# STM32MP25_CM33 register map
File version: 1.3
CPU: CM33 r0p1, little endian, MPU, FPU, vendor SysTick, 8 interrupt priority bits
Registers are 32-bit, read-write, reset 0x0 unless marked. A register's access mark holds for its fields unless they carry their own. Offsets are from the block's base; [hi:lo] are bit positions; {n}, {i} and the like mark numbered series; 'fields as' and 'values as' point back to an identical list.

## LVDS — LVDS address block description
Base 0x48060000
Same registers: LVDS_S 0x58060000
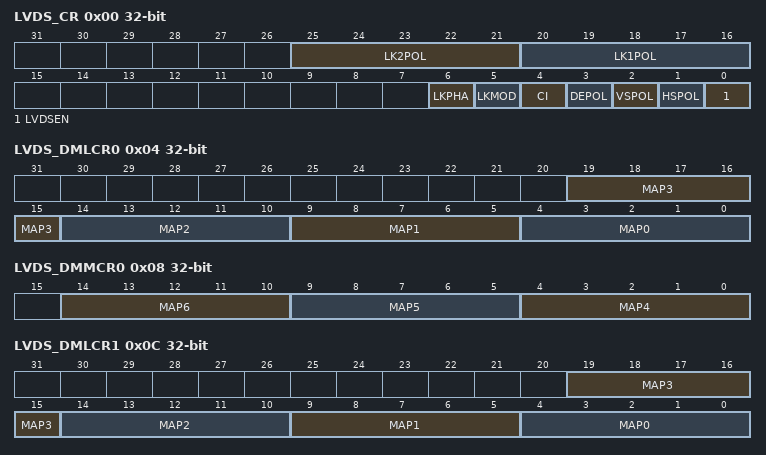
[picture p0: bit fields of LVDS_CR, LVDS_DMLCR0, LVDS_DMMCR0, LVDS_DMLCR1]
0x00 LVDS_CR — LVDS configuration register
  [25:21] LK2POL — Link-2 output polarity, defined per output data/clock lane, from Lane-[4:0]
    0=unchanged polarity; 1=inverted polarity
  [20:16] LK1POL — Link-1 output polarity, defined per output data/clock lane, from Lane-[4:0]
    0=unchanged polarity; 1=inverted polarity
  [6] LKPHA — Link phase, for both links
    0=Even pixel after odd pixel; 1=Even pixel before odd pixel
  [5] LKMOD — Link mode, for both links, which impacts the clock used The LVDS PHY generates a clock at double the pixel rate: in Single-link mode, the pixel generation is set at half the double-pixel-rate clock, while in Dual-link mode, the pixel generation is done at the double-pixel-rate, as each PHY receives half the pixel rate (seeFigure466: Display subsystem clock diagram).
    0=Single-link mode (all pixels sent to both links); 1=Dual-link mode (pixels shared between two links: even pixels to one link, odd to theother)
  [4] CI — Control internal (software controlled bit, that can be inserted among output data)
    0=a 1 and apos;b0 is inserted; 1=a 1 and apos;b1 is inserted
  [3] DEPOL — Data enable polarity
    0=unchanged polarity; 1=inverted polarity
  [2] VSPOL — Vertical synchronization polarity
    0=unchanged polarity; 1=inverted polarity
  [1] HSPOL — Horizontal synchronization polarity
    0=unchanged polarity; 1=inverted polarity
  [0] LVDSEN — LVDS PHY enable
    0=display inactive (no active pixel among the synchronization); 1=display active (active pixels among synchronization)
0x04 LVDS_DMLCR0 — LVDS data mapping LSB configuration register 0
  [19:15] MAP3 — Mapping for bit 3 of that data lane (same content definition as LVDS_DMLCR0.MAP0)
  [14:10] MAP2 — Mapping for bit 2 of that data lane (same content definition as LVDS_DMLCR0.MAP0)
  [9:5] MAP1 — Mapping for bit 1 of that data lane (same content definition as LVDS_DMLCR0.MAP0)
  [4:0] MAP0 — Mapping for bit 0 of that data lane
    0=R0; 7=R7; 8=G0; 15=G7; 16=B0; 23=B7; 24=HS (horizontal synchronization); 25=VS (vertical synchronization); 26=DE (data enable); 27=CE (constant hardware input); 28=CI (constant software input, defined in LVDS_CR.CI); 29=TOGGLE; 30=1 (constant 1&b1); 31=0 (constant 1&b0)
0x08 LVDS_DMMCR0 — LVDS data mapping MSB configuration register 0
  [14:10] MAP6 — Mapping for bit 6 of that data lane (same content definition as LVDS_DMLCR0.MAP0)
  [9:5] MAP5 — Mapping for bit 5 of that data lane (same content definition as LVDS_DMLCR0.MAP0)
  [4:0] MAP4 — Mapping for bit 4 of that data lane (same content definition as LVDS_DMLCR0.MAP0)
0x0C LVDS_DMLCR1 — LVDS data mapping LSB configuration register 1
  fields as LVDS_DMLCR0
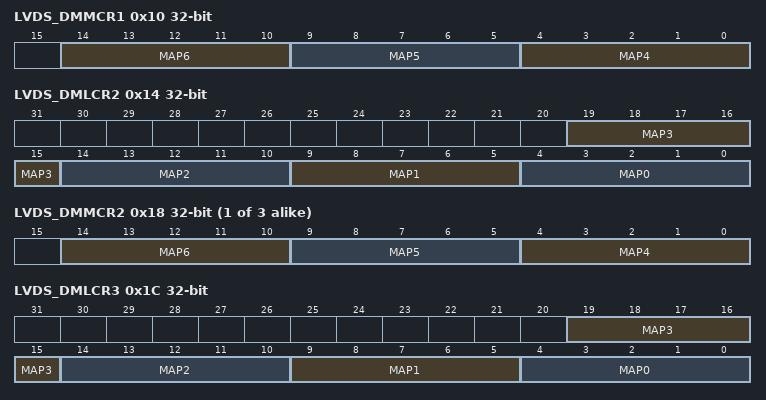
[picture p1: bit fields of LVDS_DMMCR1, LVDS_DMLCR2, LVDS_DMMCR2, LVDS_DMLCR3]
0x10 LVDS_DMMCR1 — LVDS data mapping MSB configuration register 1
  fields as LVDS_DMMCR0
0x14 LVDS_DMLCR2 — LVDS data mapping LSB configuration register 2
  [19:15] MAP3 — Mapping for bit 3 of that DataLane. (same content definition as LVDS_DMLCR0.MAP0)
  [14:10] MAP2 — Mapping for bit 2 of that DataLane. (same content definition as LVDS_DMLCR0.MAP0)
  [9:5] MAP1 — Mapping for bit 1 of that DataLane. (same content definition as LVDS_DMLCR0.MAP0)
  [4:0] MAP0 — Mapping for bit 0 of that DataLane.
    values as LVDS_DMLCR0.MAP0
{0x8+8i} LVDS_DMMCR{i} (i=2..4) — LVDS data mapping MSB configuration register {i}
  [14:10] MAP6 — Mapping for bit 6 of that DataLane. (same content definition as LVDS_DMLCR0.MAP0)
  [9:5] MAP5 — Mapping for bit 5 of that DataLane. (same content definition as LVDS_DMLCR0.MAP0)
  [4:0] MAP4 — Mapping for bit 4 of that DataLane. (same content definition as LVDS_DMLCR0.MAP0)
0x1C LVDS_DMLCR3 — LVDS data mapping LSB configuration register 3
  [19:15] MAP3 — Mapping for bit 3 of that DataLane. (same content definition as LVDS_DMLCR0.MAP0)
  [14:10] MAP2 — Mapping for bit 2 of that DataLane. (same content definition as LVDS_DMLCR0.MAP0)
  [9:5] MAP1 — Mapping for bit 1 of that DataLane. (same content definition as LVDS_DMLCR0.MAP0)
  [4:0] MAP0 — Mapping for bit 0 of that DataLane.
    0=R0; 7=R7; 8=G0; 15=G7; 16=B0; 23=B7; 24=HS (horizontal synchronization); 25=VS (vertical synchronization); 26=DE (data enable); 27=CE (constant hardware input); 28=CI (constant software input, defined in LVDS_CR.CI); 29=TOGGLE; 30=1 (constant 1and apos; b1); 31=0 (constant 1and apos; b0)
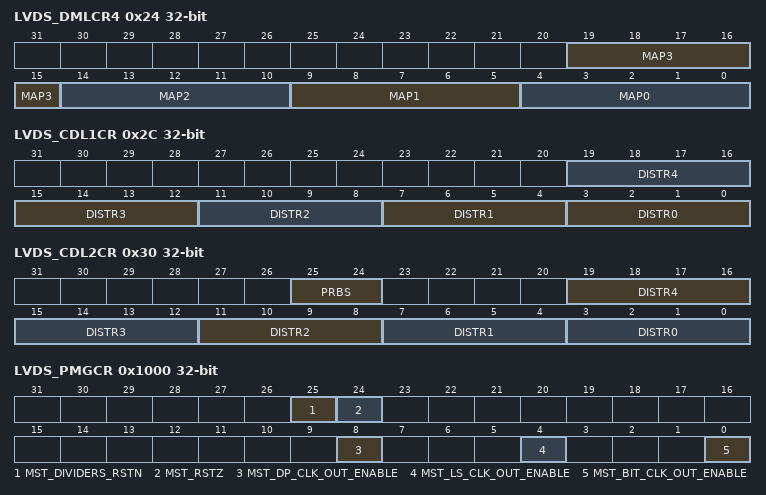
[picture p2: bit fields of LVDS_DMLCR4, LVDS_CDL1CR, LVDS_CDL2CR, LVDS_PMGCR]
0x24 LVDS_DMLCR4 — LVDS data mapping LSB configuration register 4
  fields as LVDS_DMLCR2
0x2C LVDS_CDL1CR — LVDS channel distribution link 1configuration register
  [4n+3:4n] DISTR{n} (n=1..4) — channel distribution for Lane {n} (same content definition as LVDS_CDL1CR.DISTR0)
  [3:0] DISTR0 — channel distribution for Lane 0 Other: Reserved
    {v}=Channel {v} odd (v=0..4); {v}=Channel {v-5} even (v=5..9); 10=PRBS
0x30 LVDS_CDL2CR — LVDS channel distribution link 2 configuration register
  [25:24] PRBS — PRBS polynomial type
    0=PRBS7, with: x7 + x6 + 1; 1=PRBS15, with: x15 + x14 + 1; 2=PRBS23, with: x23 + x18 + 1; 3=PRBS31, with: x31 + x28 + 1
  [4n+3:4n] DISTR{n} (n=1..4) — channel distribution for Lane {n} (same content definition as LVDS_CDL1CR.DISTR0)
  [3:0] DISTR0 — channel distribution for Lane 0 Other: Reserved
    0=Channel 0 odd; 1=Channel 1 even; 2=Channel 2 odd; 3=Channel 3 even; 4=Channel 4 odd; 5=Channel 0 even; 6=Channel 6 odd; 7=Channel 7 even; 8=Channel 8 odd; 9=Channel 4 even; 10=PRBS
0x1000 LVDS_PMGCR — LVDS PHY-Master global control register
  [25] MST_DIVIDERS_RSTN — Output divider reset
    0=output divider is reset; 1=output divider is working
  [24] MST_RSTZ — When set to 0, this bit places the LVDS-PHY digital section in reset state.
  [8] MST_DP_CLK_OUT_ENABLE — Enable LVDS-PHY dp_clk clock
    0=disable; 1=enable
  [4] MST_LS_CLK_OUT_ENABLE — Enable LVDS-PHY ls_clk clock
    0=disable; 1=enable
  [0] MST_BIT_CLK_OUT_ENABLE — Enable LVDS-PHY bit_clk clock
    0=disable; 1=enable
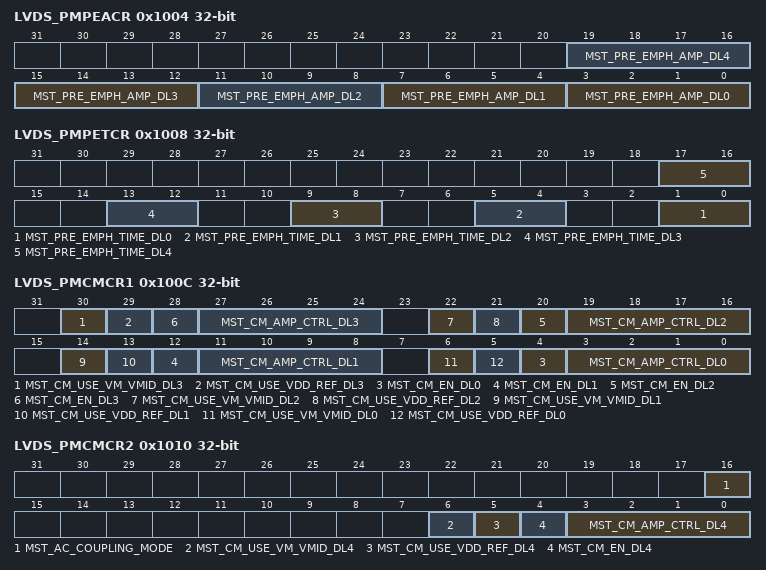
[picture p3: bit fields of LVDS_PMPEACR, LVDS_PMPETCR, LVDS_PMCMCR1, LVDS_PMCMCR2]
0x1004 LVDS_PMPEACR — LVDS PHY-Master pre-emphasis amplitude control register
  [4n+3:4n] MST_PRE_EMPH_AMP_DL{n} (n=1..4) — Amplitude control for pre-emphasis for lane{n}
  [3:0] MST_PRE_EMPH_AMP_DL0 — Amplitude control for pre-mphasis for lane0
0x1008 LVDS_PMPETCR — LVDS PHY-Master pre-emphasis time control register
  [all] fields
    0=no pre-emphasis; 1=1-bit pre-emphasis; 2=1/2 bit pre-emphasis
  [4n+1:4n] MST_PRE_EMPH_TIME_DL{n} (n=0..4) — Time duration control for pre-emphasis for lane{n}
0x100C LVDS_PMCMCR1 — LVDS PHY-Master current mode control register 1
  [30] MST_CM_USE_VM_VMID_DL3 — common mode of datalane3 When high, reference is mid voltage of the driver levels.
  [29] MST_CM_USE_VDD_REF_DL3 — common mode of data lane3 When high, reference is derived from AVDD_IO voltage.
  [8n+4] MST_CM_EN_DL{n} (n=0..3) — Enable for current mode driver, data lane{n}
  [8n+3:8n] MST_CM_AMP_CTRL_DL{n} (n=0..3) — Amplitude control for current mode driver, data lane{n}
  [22] MST_CM_USE_VM_VMID_DL2 — common mode of data lane2 When high, reference is mid voltage of the driver levels.
  [21] MST_CM_USE_VDD_REF_DL2 — common mode of data lane2 When high, reference is derived from AVDD_IO voltage.
  [14] MST_CM_USE_VM_VMID_DL1 — common mode of data lane1 When high, reference is mid voltage of the driver levels.
  [13] MST_CM_USE_VDD_REF_DL1 — common mode of data lane1 When high, reference is derived from AVDD_IO voltage.
  [6] MST_CM_USE_VM_VMID_DL0 — common mode of data lane0 When high, reference is mid voltage of the driver levels.
  [5] MST_CM_USE_VDD_REF_DL0 — common mode of datalane0 When high, reference is derived from AVDD_IO voltage.
0x1010 LVDS_PMCMCR2 — LVDS PHY-Master current mode control register 2
  [16] MST_AC_COUPLING_MODE — AC Coupling Mode.
  [6] MST_CM_USE_VM_VMID_DL4 — common mode of data lane4 When high, reference is mid voltage of the driver level.
  [5] MST_CM_USE_VDD_REF_DL4 — common mode of data lane4 When high, reference is derived from AVDD_IO voltage.
  [4] MST_CM_EN_DL4 — Enable for current mode driver, data lane4
  [3:0] MST_CM_AMP_CTRL_DL4 — Amplitude control for current mode driver, data lane4
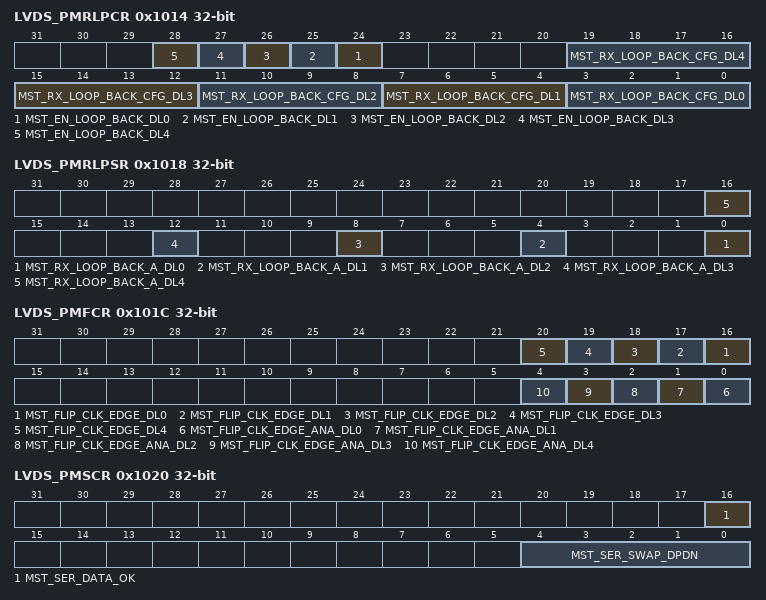
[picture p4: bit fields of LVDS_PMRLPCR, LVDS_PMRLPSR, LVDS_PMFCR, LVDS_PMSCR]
0x1014 LVDS_PMRLPCR — LVDS PHY-Master Rx loopback control register
  [n+24] MST_EN_LOOP_BACK_DL{n} (n=0..4) — Enable the loop back RX used for continuous monitoring, datalane{n}
  [4n+3:4n] MST_RX_LOOP_BACK_CFG_DL{n} (n=0..4) — Rx loop back configuration for data lane{n}
    0=RX input connected to output pads (clk comp: enabled, comp: disabled); 1=RX input connected before termination (clk comp: enabled, comp: disabled); 2=RX input connected to output pads (clk comp: disabled, comp: enabled); 3=RX input connected before termination (clk comp: disabled, comp: enabled)
0x1018 LVDS_PMRLPSR ro — LVDS PHY-master Rx loopback status register
  [4n] MST_RX_LOOP_BACK_A_DL{n} (n=0..4) — Rx loop back output for lane{n}
0x101C LVDS_PMFCR — LVDS PHY-Master flipedge control register
  [n+16] MST_FLIP_CLK_EDGE_DL{n} (n=0..4) — Flips the clock edge used by the first analog stage to resample the incoming data stream, data lane{n}
  [n] MST_FLIP_CLK_EDGE_ANA_DL{n} (n=0..4) — Flips the clock edge used by the pre-driver, data lane{n}
0x1020 LVDS_PMSCR — LVDS PHY-Master serial control register
  [16] MST_SER_DATA_OK — Indicates transmission of data
    0=No transmission; 1=Transmission
  [4:0] MST_SER_SWAP_DPDN — Inverts output data (1 bit per lane
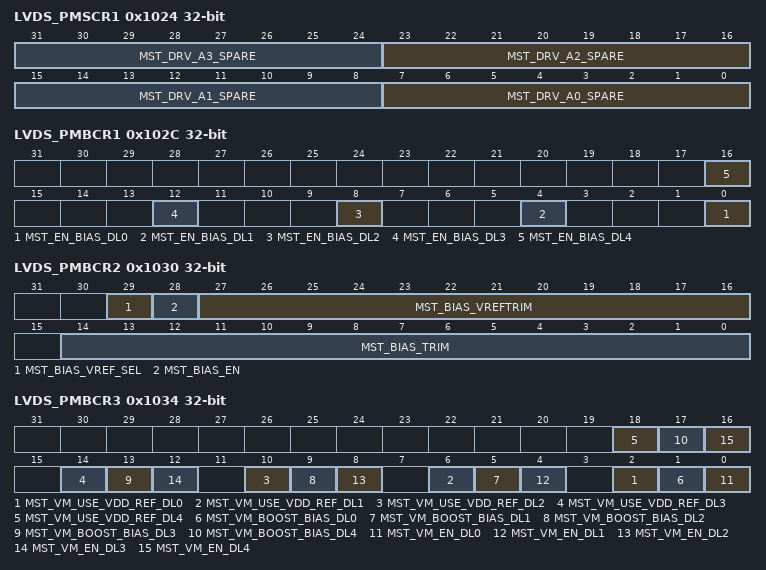
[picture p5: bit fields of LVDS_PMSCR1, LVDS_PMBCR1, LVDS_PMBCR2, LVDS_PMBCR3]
0x1024 LVDS_PMSCR1 — LVDS PHY-Master spare control register 1
  [8n+7:8n] MST_DRV_A{n}_SPARE (n=0..3) — Spare inputs for data lane{n}
0x1028 LVDS_PMSCR2 — LVDS PHY-Master spare control register 2
  [7:0] MST_DRV_A4_SPARE — Spare inputs for data lane4
0x102C LVDS_PMBCR1 — LVDS PHY-Master bias control register 1
  [all] fields
    0=disable; 1=enable
  [4n] MST_EN_BIAS_DL{n} (n=0..4) — Enable the local bias at data lane{n}
0x1030 LVDS_PMBCR2 — LVDS PHY-Master bias control register 2
  [29] MST_BIAS_VREF_SEL — Selection for current generation internal reference
    0=from the bandgap; 1=from an internal resistive divider
  [28] MST_BIAS_EN — LVDS macro global bias enable
    0=disabled; 1=enabled
  [27:16] MST_BIAS_VREFTRIM
    1=0.3961V, 27.01 uA; 2=0.4252 V, 23.36 uA; 4=0.4542 V, 24.96 uA; 8=0.4831 V, 26.57 uA; 16=0.5120 V, 28.21 uA; 32=0.5410 V, 29.90 uA; 64=0.5698 V, 31.66 uA; 128=0.5985 V, 33.54 uA; 0x100=0.6272 V, 35.70 uA; 0x201=0.6557 V, 38.63 uA; 0x400=0.6838 V, 43.98 uA; 0x800=0.7107 V, 56.97 uA
  [14:0] MST_BIAS_TRIM — 0x0: 27.71 uA
    1=27.01 uA; 3=26.32 uA; 7=25.63 uA; 15=24.94 uA; 31=24.24 uA; 63=23.55 uA; 127=22.86 uA; 255=23.55 uA; 0x1FF=24.24 uA; 0x3FF=24.94 uA; 0x7FF=25.63 uA; 0xFFF=26.32 uA; 0x1FFF=27.01 uA; 0x3FFF=27.71 uA; 0x7FFF=28.40 uA
0x1034 LVDS_PMBCR3 — LVDS PHY-Master bias control register 3
  [4n+2] MST_VM_USE_VDD_REF_DL{n} (n=0..4) — Sets the voltage mode driver to use a reference derived from the power supply, data lane{n}
  [4n+1] MST_VM_BOOST_BIAS_DL{n} (n=0..4) — Bias booster for the voltage mode driver LDOS, data lane{n}
    0=bandgap selected; 1=internal resistive divider
  [4n] MST_VM_EN_DL{n} (n=0..4) — Enable the voltage mode driver for data lane{n}
    0=disable; 1=enable
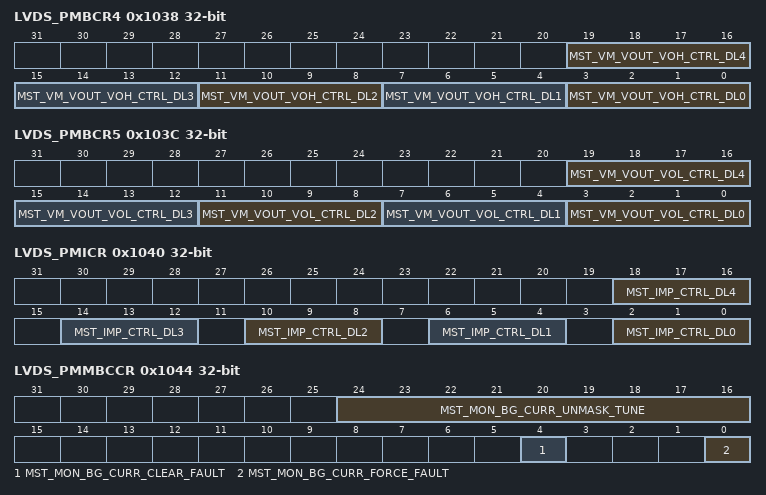
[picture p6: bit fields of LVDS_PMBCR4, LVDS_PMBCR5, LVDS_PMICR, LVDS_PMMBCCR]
0x1038 LVDS_PMBCR4 — LVDS PHY-Master bias control register 4
  [4n+3:4n] MST_VM_VOUT_VOH_CTRL_DL{n} (n=0..4) — Fine tuning for the voltage mode driver VOH, datalane{n}
0x103C LVDS_PMBCR5 — LVDS PHY-Master bias control register 5
  [4n+3:4n] MST_VM_VOUT_VOL_CTRL_DL{n} (n=0..4) — Fine tuning for the voltage mode driver VOL, datalane{n}
0x1040 LVDS_PMICR — LVDS PHY-Master impedance control register
  [18:16] MST_IMP_CTRL_DL4 — Impedance control for data lane4
  [14:12] MST_IMP_CTRL_DL3 — Impedance control for data lane3
  [10:8] MST_IMP_CTRL_DL2 — Impedance control for data lane0
  [6:4] MST_IMP_CTRL_DL1 — Impedance control for data lane1
  [2:0] MST_IMP_CTRL_DL0 — Impedance control for data lane0
0x1044 LVDS_PMMBCCR — LVDS PHY-Master monitor bandgap current control register
  [24:16] MST_MON_BG_CURR_UNMASK_TUNE — Bandgap current timing control for the monitor unmask after startup
  [4] MST_MON_BG_CURR_CLEAR_FAULT — Bandgap current monitor clear fault If set high, lvds_monitor_bg_curr_fault_mst is cleared. It has to be set low again in order to continue monitoring the bandgap current.
  [0] MST_MON_BG_CURR_FORCE_FAULT — Bandgap current monitor force fault If set high, force the lvds_monitor_bg_curr_fault_mst and lvds_monitor_bg_curr_permanent_fault_mst to indicate a fault. This force is only removed once it goes low again
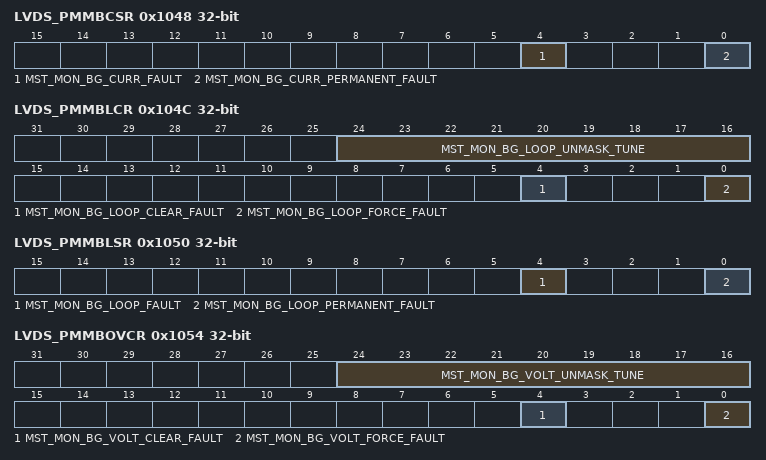
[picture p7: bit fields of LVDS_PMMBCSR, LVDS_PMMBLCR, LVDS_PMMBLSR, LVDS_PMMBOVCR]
0x1048 LVDS_PMMBCSR ro — LVDS PHY-Master monitor bandgap current status register
  [4] MST_MON_BG_CURR_FAULT — Bandgap current monitor fault Indicates that a fault has occurred when high. This signal is latched in the LVDS PHY, so it is kept high until cleared by mst_mon_bg_curr_clear_fault_mst.
  [0] MST_MON_BG_CURR_PERMANENT_FAULT — Bandgap current monitor permanent fault Indicates that a fault is occurring when high. If mst_mon_bg_curr_fault_mst is high and mst_bg_curr_permanent_fault_mst is low, the fault was a glitch that has since faded. If mst_mon_bg_curr_fault_mst is high and mst_bg_curr_permanent_fault_mst is high, the fault is still occurring.
0x104C LVDS_PMMBLCR — LVDS PHY-Master monitor bandgap loop control register
  [24:16] MST_MON_BG_LOOP_UNMASK_TUNE — Bandgap loop timing control for the monitor unmask after startup
  [4] MST_MON_BG_LOOP_CLEAR_FAULT — Bandgap loop monitor clear fault If set high, lvds_monitor_bg_loop_fault_mst is cleared. It has to be set low again in order to continue monitoring the bandgap loop
  [0] MST_MON_BG_LOOP_FORCE_FAULT — Bandgap loop monitor force fault If set high, force the lvds_monitor_bg_loop_fault_mst and lvds_monitor_bg_loop_permanent_fault_mst to indicate a fault. This force is only removed once it goes low again
0x1050 LVDS_PMMBLSR ro — LVDS PHY-Master monitor bandgap loop status register
  [4] MST_MON_BG_LOOP_FAULT — Bandgap loop monitor fault Indicates that a fault has occurred when high. This signal is latched in the LVDS PHY, so it is kept high until cleared by mst_mon_bg_loop_clear_fault_mst.
  [0] MST_MON_BG_LOOP_PERMANENT_FAULT — Bandgap loop monitor permanent fault Indicates that a fault is occurring when high. If mst_mon_bg_loop_fault_mst is high and mst_bg_loop_permanent_fault_mst is low, the fault was a glitch that has since faded. If mst_mon_bg_loop_fault_mst is high and mst_bg_loop_permanent_fault_mst is high, the fault is still occurring.
0x1054 LVDS_PMMBOVCR — LVDS PHY-Master monitor bandgap output voltage control register
  [24:16] MST_MON_BG_VOLT_UNMASK_TUNE — Bandgap output voltage timing control for the monitor unmask after startup
  [4] MST_MON_BG_VOLT_CLEAR_FAULT — Bandgap output voltage monitor clear fault If set high, lvds_monitor_bg_volt_fault_mst is cleared. It has to be set low again in order to continue monitoring the bandgap output voltage
  [0] MST_MON_BG_VOLT_FORCE_FAULT — Bandgap output voltage monitor force fault If set high, force the lvds_monitor_bg_volt_fault_mst and lvds_monitor_bg_volt_permanent_fault_mst to indicate a fault. This force is only removed once it goes low again
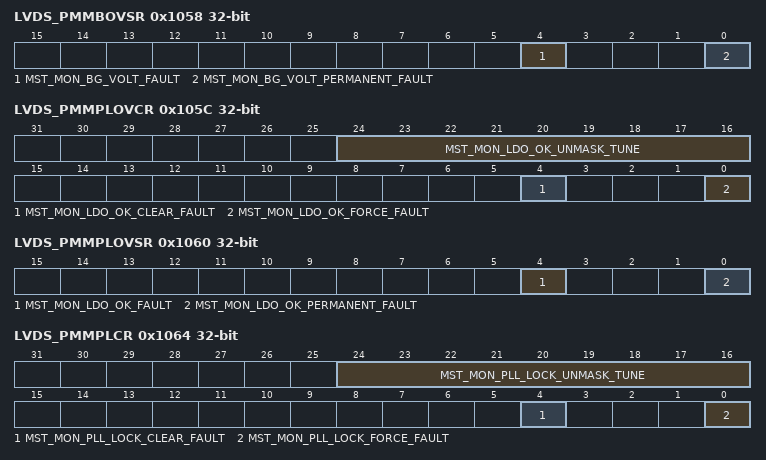
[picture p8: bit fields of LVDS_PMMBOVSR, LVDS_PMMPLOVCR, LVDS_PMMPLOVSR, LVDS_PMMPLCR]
0x1058 LVDS_PMMBOVSR ro — LVDS PHY-Master monitor bandgap output voltage status register
  [4] MST_MON_BG_VOLT_FAULT — Bandgap output voltage monitor fault Indicates that a fault has occurred when high. This signal is latched in the LVDS PHY, so it is kept high until cleared by mst_mon_bg_volt_clear_fault_mst.
  [0] MST_MON_BG_VOLT_PERMANENT_FAULT — Bandgap output voltage monitor permanent fault Indicates that a fault is occurring when high. If mst_mon_bg_volt_fault_mst is high and mst_bg_volt_permanent_fault_mst is low, the fault was a glitch that has since faded. If mst_mon_bg_volt_fault_mst is high and mst_bg_volt_permanent_fault_mst is high, the fault is still occurring.
0x105C LVDS_PMMPLOVCR — LVDS PHY-Master monitor PLL LDO output voltage control register
  [24:16] MST_MON_LDO_OK_UNMASK_TUNE — PLL LDO output voltage timing control for the monitor unmask after startup
  [4] MST_MON_LDO_OK_CLEAR_FAULT — PLL LDO output voltage monitor clear fault If set high, lvds_monitor_ldo_ok_fault_mst is cleared. It has to be set low again in order to continue monitoring the PLL LDO output voltage
  [0] MST_MON_LDO_OK_FORCE_FAULT — PLL LDO output voltage monitor force fault If set high, force the lvds_monitor_ldo_ok_fault_mst and lvds_monitor_ldo_ok_permanent_fault_mst to indicate a fault. This force is only removed once it goes low again
0x1060 LVDS_PMMPLOVSR ro — LVDS PHY-Master monitor PLL LDO output voltage status register
  [4] MST_MON_LDO_OK_FAULT — PLL LDO output voltage monitor fault Indicates that a fault has occurred when high. This signal is latched in the LVDS PHY, so it is kept high until cleared by mst_mon_ldo_ok_clear_fault_mst.
  [0] MST_MON_LDO_OK_PERMANENT_FAULT — PLL LDO output voltage monitor permanent fault Indicates that a fault is occurring when high. If mst_mon_ldo_ok_fault_mst is high and mst_ldo_ok_permanent_fault_mst is low, the fault was a glitch that has since faded. If mst_mon_ldo_ok_fault_mst is high and mst_ldo_ok_permanent_fault_mst is high, the fault is still occurring.
0x1064 LVDS_PMMPLCR — LVDS PHY-Master monitor PLL lock control register
  [24:16] MST_MON_PLL_LOCK_UNMASK_TUNE — PLL Lock timing control for the monitor unmask after startup
  [4] MST_MON_PLL_LOCK_CLEAR_FAULT — PLL Lock monitor clear fault If set high, lvds_monitor_pll_lock_fault_mst is cleared. It has to be set low again in order to continue monitoring the PLL lock
  [0] MST_MON_PLL_LOCK_FORCE_FAULT — PLL Lock monitor force fault If set high, force the lvds_monitor_pll_lock_fault_mst and lvds_monitor_pll_lock_permanent_fault_mst to indicate a fault. This force is only removed once it goes low again
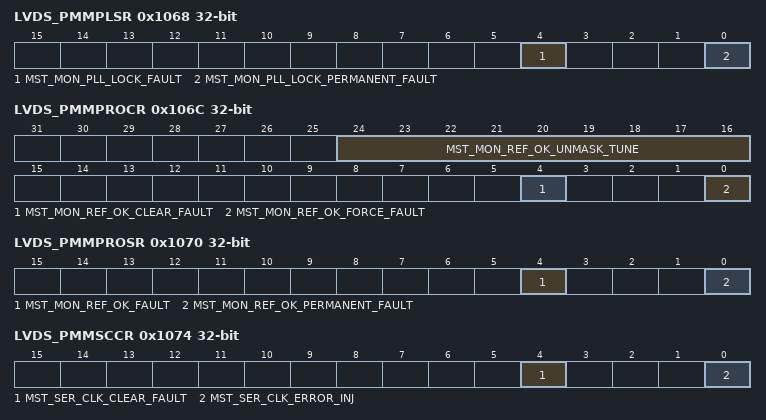
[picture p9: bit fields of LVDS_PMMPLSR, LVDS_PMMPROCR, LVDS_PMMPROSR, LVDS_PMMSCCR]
0x1068 LVDS_PMMPLSR ro — LVDS PHY-Master monitor PLL lock status register
  [4] MST_MON_PLL_LOCK_FAULT — PLL Lock monitor fault Indicates that a fault has occurred when high. This signal is latched in the LVDS PHY, so it is kept high until cleared by mst_mon_pll_lock_clear_fault_mst
  [0] MST_MON_PLL_LOCK_PERMANENT_FAULT — PLL Lock monitor permanent fault Indicates that a fault is occurring when high. If mst_mon_pll_lock_fault_mst is high and mst_pll_lock_permanent_fault_mst is low, the fault was a glitch that has since faded If mst_mon_pll_lock_fault_mst is high and mst_pll_lock_permanent_fault_mst is high, the fault is still occurring
0x106C LVDS_PMMPROCR — LVDS PHY-Master monitor PLL reference OK control register
  [24:16] MST_MON_REF_OK_UNMASK_TUNE — PLL Reference timing control for the monitor unmask after startup
  [4] MST_MON_REF_OK_CLEAR_FAULT — PLL Reference monitor clear fault If set high, lvds_monitor_ref_ok_fault_mst is cleared. It has to be set low again in order to continue monitoring the PLL Reference
  [0] MST_MON_REF_OK_FORCE_FAULT — PLL Reference monitor force fault If set high, force the lvds_monitor_ref_ok_fault_mst and lvds_monitor_ref_ok_permanent_fault_mst to indicate a fault. This force is only removed once it goes low again
0x1070 LVDS_PMMPROSR ro — LVDS PHY-Master monitor PLL reference OK status register
  [4] MST_MON_REF_OK_FAULT — PLL Reference OK monitor fault Indicates that a fault has occurred when high. This signal is latched in the LVDS PHY, so it is kept high until cleared by mst_mon_ref_ok_clear_fault_mst
  [0] MST_MON_REF_OK_PERMANENT_FAULT — PLL Reference OK monitor permanent fault Indicates that a fault is occurring when high. If mst_mon_ref_ok_fault_mst is high and mst_ref_ok_permanent_fault_mst is low, the fault was a glitch that has since faded If mst_mon_ref_ok_fault_mst is high and mst_ref_ok_permanent_fault_mst is high, the fault is still occurring
0x1074 LVDS_PMMSCCR — LVDS PHY-Master monitor serializer clock control register
  [4] MST_SER_CLK_CLEAR_FAULT — Serializer clock checking fault clearing
  [0] MST_SER_CLK_ERROR_INJ — Serializer clock checking error injection
0x1078 LVDS_PMMSCSR ro — LVDS PHY-Master monitor serializer clock status register
  [0] MST_SER_CLK_FAULT — Serializer clock checking fault
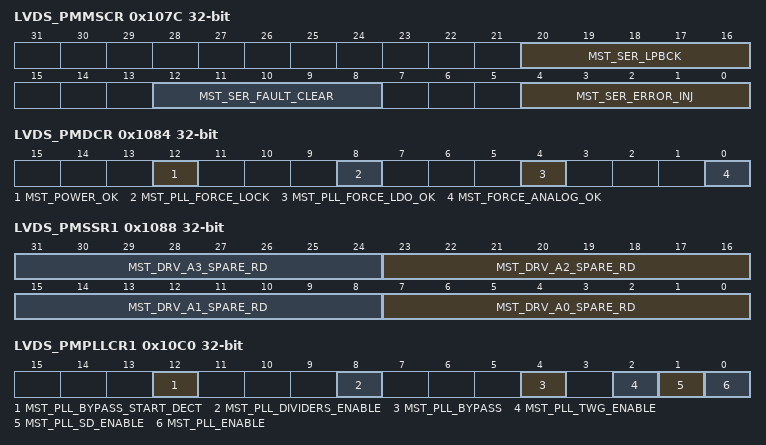
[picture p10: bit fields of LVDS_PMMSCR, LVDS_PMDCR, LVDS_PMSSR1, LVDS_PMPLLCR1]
0x107C LVDS_PMMSCR — LVDS PHY-Master monitor serializer control register
  [20:16] MST_SER_LPBCK — Serializer fault loopback
  [12:8] MST_SER_FAULT_CLEAR — Serializer fault clearing
  [4:0] MST_SER_ERROR_INJ — Serializer error injection
0x1080 LVDS_PMMSSR ro — LVDS PHY-Master monitor serializer status register
  [4:0] MST_SER_FAULT — Serializer fault
0x1084 LVDS_PMDCR — LVDS PHY-Master debug control register
  [12] MST_POWER_OK — When set to 1, this bit masks some functions in the LVDS-PHY This bit can be used as a work around to functional problems with some of the monitor blocks
  [8] MST_PLL_FORCE_LOCK — When set to 1, this bit masks some functions in the LVDS-PHY This bit can be used as a work around to functional problems with some of the monitor blocks
  [4] MST_PLL_FORCE_LDO_OK — When set to 1, this bit masks some functions in the LVDS-PHY This bit can be used as a work around to functional problems with some of the monitor blocks
  [0] MST_FORCE_ANALOG_OK — When set to 1, this bit masks some functions in the LVDS-PHY This bit can be used as a work around to functional problems with some of the monitor blocks
0x1088 LVDS_PMSSR1 ro — LVDS PHY-Master spare status register 1
  [8n+7:8n] MST_DRV_A{n}_SPARE_RD (n=0..3) — Spare outputs for data lane{n}
0x108C LVDS_PMSSR2 ro — LVDS PHY-Master spare status register 2
  [7:0] MST_DRV_A4_SPARE_RD — Spare outputs for data lane4
0x10A0 LVDS_PMCFGCR — LVDS PHY-Master configuration control register
  [4:0] MST_EN_DIG_DL — Enables Digital DataLanes DL4...DL0
0x10C0 LVDS_PMPLLCR1 — LVDS PHY-Master PLL_MODE 1 control register
  [12] MST_PLL_BYPASS_START_DECT ro — Bypass start DECT.
  [8] MST_PLL_DIVIDERS_ENABLE — 0x0: Dividers disabled
    1=Dividers enabled
  [4] MST_PLL_BYPASS — 0x0: from VCO output
    1=from external (lvds_pll_clk_bypass_2g2)
  [2] MST_PLL_TWG_ENABLE — Triangular wave pattern used to modulate MDIV
    0=Triangular Wave generator powered down; 1=Triangular wave generator enable (not recommended if integer N PLL mode is selected)
  [1] MST_PLL_SD_ENABLE — sigma-delta enable
    0=disable (Integer N PLL mode); 1=enable (fractional N PLL mode if mst_pll_twg_enable=0 , spread spectrum clocking if mst_pll_twg_enable=1)
  [0] MST_PLL_ENABLE — 0x0: LVDS-PHY PLL Disable
    1=LVDS-PHY PLL Enable
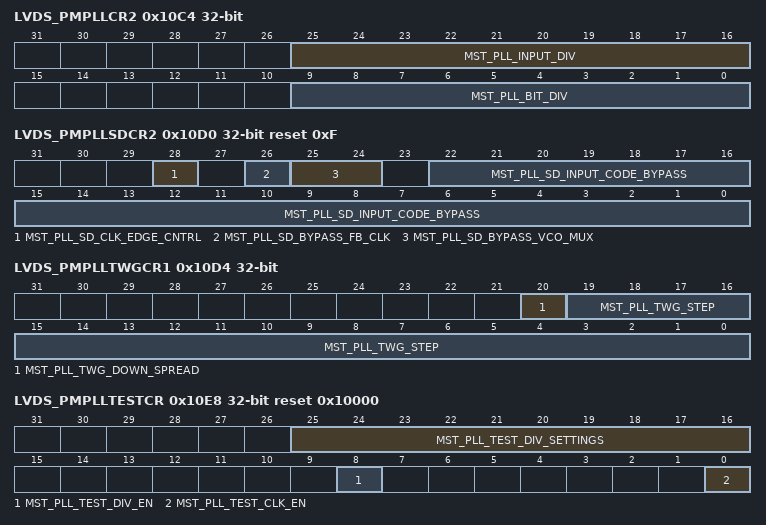
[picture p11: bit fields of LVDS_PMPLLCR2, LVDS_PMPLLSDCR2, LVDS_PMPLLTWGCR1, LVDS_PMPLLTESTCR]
0x10C4 LVDS_PMPLLCR2 — LVDS PHY-Master PLL_MODE 2 control register
  [25:16] MST_PLL_INPUT_DIV — PLL Input Clock Divider (NDIV, divides input reference clock)
    1=B_d1 (minimal value)
  [9:0] MST_PLL_BIT_DIV — PLL Output Clock Divider (BDIV, divides output VCO)
    2=B_d2 (minimal value)
0x10C8 LVDS_PMPLLSR ro — LVDS PHY-Master PLL status register
  [0] MST_PLL_LOCK — PLL lock During a certain number of cycles of reference clock, pll_lock is asserted high and then goes low waiting for the LVDS-PHY PLL t0 lock
0x10CC LVDS_PMPLLSDCR1 — LVDS PHY-Master PLL_SD_1 control register
  [9:0] MST_PLL_SD_INT_RATIO — Integer Setting of PLL Feedback Clock Divider (MDIV, divides VCO clock for feedback) MDIV divider is used for both integer N and Fractional N PLL modes: - Integer N: MDIV = mst_pll_sd_int_ratio[9:0] (for integer setting) mst_pll_sd_bypass_vco_mux is not used. - Fractional N: MDIV = mst_pll_sd_int_ratio[9:0] (for integer setting), mst_pll_sd_input_code_bypass[22:0] (for fractional setting). MDIV = mst_pll_sd_int_ratio[9:0] + (mst_pll_sd_input_code_bypass[22:0 - 4194304)/131072
0x10D0 LVDS_PMPLLSDCR2 reset 0xF — LVDS PHY-Master PLL_SD_2 control register
  [28] MST_PLL_SD_CLK_EDGE_CNTRL — Sigma Delta Edge Control.
  [26] MST_PLL_SD_BYPASS_FB_CLK ro — Bypass start SD feedback clock.
  [25:24] MST_PLL_SD_BYPASS_VCO_MUX — Bypass control for the PLL sigma delta VCO mux
  [22:0] MST_PLL_SD_INPUT_CODE_BYPASS — Fractional Setting of PLL Feedback Clock Divider (MDIV, divides VCO clock for feedback)
0x10D4 LVDS_PMPLLTWGCR1 — LVDS PHY-Master PLL_TWG_1 control register
  [20] MST_PLL_TWG_DOWN_SPREAD — TWG pattern spreading
    0=center spread; 1=down spread
  [19:0] MST_PLL_TWG_STEP — MDIV divdier used in integer N and Fractional N PLL modes integer N: mst_pll_sd_bypass_vco_mux is not relevant. MDIV = mst_pll_sd_int_ratio[9:0] fractional N: MDIV controlled by mst_pll_sd_int_ratio[9:0] and mst_pll_sd_input_code_bypass[22:0] MDIV = mst_pll_sd_int_ratio[9:0] + (mst_pll_sd_input_code_bypass[22:0 - 4194304)/131072
0x10D8 LVDS_PMPLLTWGCR2 — LVDS PHY-Master PLL_TWG_2 control register
  [22:0] MST_PLL_TWG_THRESHOLD — TWG_THRESHOLD setting
0x10DC LVDS_PMPLLLDOCR — LVDS PHY-Master PLL_LDO control register
  [2:0] MST_PLL_LDO_FRREGVTRIM — PLL LDO output voltage fine tuning:
    0=1.459 V; 1=1.698 V; 2=1.651 V; 3=1.609 V; 4=1.568 V; 5=1.530 V; 6=1.494 V; 7=1.744 V
0x10E0 LVDS_PMPLLCPCR — LVDS PHY-Master PLL_CP control register
  [3:0] MST_PLL_CPCTRL — PLL charge pump control, default=1.
0x10E4 LVDS_PMPLLCFGCR — LVDS PHY-Master PLL_CFG control register
  [7:0] MST_PLL_CFG — PLL configuration
0x10E8 LVDS_PMPLLTESTCR reset 0x10000 — LVDS PHY-Master PLL_TEST control register
  [25:16] MST_PLL_TEST_DIV_SETTINGS — lvds_pll_test_clk dividers value
  [8] MST_PLL_TEST_DIV_EN — lvds_pll_test_clk dividers enable
    0=disable; 1=enable
  [0] MST_PLL_TEST_CLK_EN — lvds_pll_test_clk enable
    0=disable; 1=enable
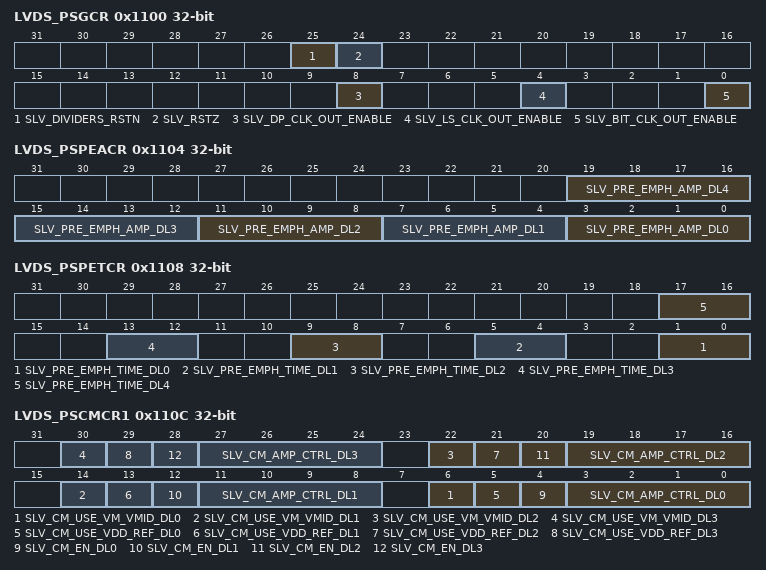
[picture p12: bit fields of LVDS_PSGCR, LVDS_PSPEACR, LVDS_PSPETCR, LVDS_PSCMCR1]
0x1100 LVDS_PSGCR — LVDS PHY-Slave global control register
  [25] SLV_DIVIDERS_RSTN — When set to 0, reset the output dividers
  [24] SLV_RSTZ — When set to 0, this bit places the digital section of the LVDS-PHY in the reset state
  [8] SLV_DP_CLK_OUT_ENABLE — Enable LVDS-PHY dp_clk clock
    0=disable; 1=enable
  [4] SLV_LS_CLK_OUT_ENABLE — Enable LVDS-PHY ls_clk clock
    0=disable; 1=enable
  [0] SLV_BIT_CLK_OUT_ENABLE — Enable LVDS-PHY bit_clk clock
    0=disable; 1=enable
0x1104 LVDS_PSPEACR — LVDS PHY-Slave pre-emphasis amplitude control register
  [4n+3:4n] SLV_PRE_EMPH_AMP_DL{n} (n=0..4) — Amplitude control for pre-emphasis for lane{n}
0x1108 LVDS_PSPETCR — LVDS PHY-Slave pre-emphasis time control register
  [all] fields
    values as the fields of LVDS_PMPETCR
  [4n+1:4n] SLV_PRE_EMPH_TIME_DL{n} (n=0..4) — Time duration control for pre-emphasis for lane{n}
0x110C LVDS_PSCMCR1 — LVDS PHY-Slave current mode control register 1
  [8n+6] SLV_CM_USE_VM_VMID_DL{n} (n=0..3) — common mode of datalane{n}: when high, reference is mid voltage of the driver levels
  [8n+5] SLV_CM_USE_VDD_REF_DL{n} (n=0..3) — common mode of datalane{n}: when high, reference is derived from AVDD_IO voltage
  [8n+4] SLV_CM_EN_DL{n} (n=0..3) — Enable for current mode driver, data lane{n}
  [8n+3:8n] SLV_CM_AMP_CTRL_DL{n} (n=0..3) — Amplitude control for current mode driver, data lane{n}
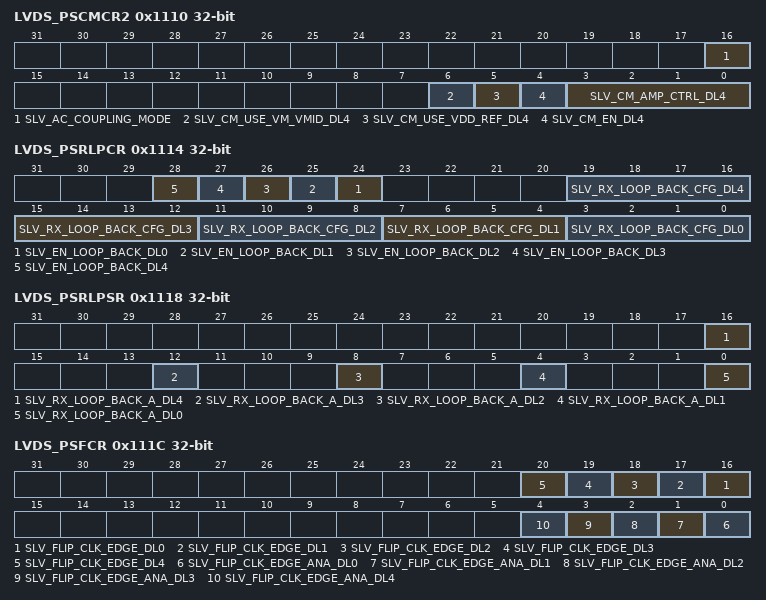
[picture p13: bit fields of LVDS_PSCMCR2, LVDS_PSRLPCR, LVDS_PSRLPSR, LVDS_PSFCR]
0x1110 LVDS_PSCMCR2 — LVDS PHY-Slave current mode control register 2
  [16] SLV_AC_COUPLING_MODE — AC Coupling Mode.
  [6] SLV_CM_USE_VM_VMID_DL4 — common mode of datalane4: when high, reference is mid voltage of the driver levels
  [5] SLV_CM_USE_VDD_REF_DL4 — common mode of datalane4: when high, reference is derived from AVDD_IO voltage
  [4] SLV_CM_EN_DL4 — Enable for current mode driver, data lane4
  [3:0] SLV_CM_AMP_CTRL_DL4 — Amplitude control for current mode driver, data lane4
0x1114 LVDS_PSRLPCR — LVDS PHY-Slave Rx loopback control register
  [n+24] SLV_EN_LOOP_BACK_DL{n} (n=0..4) — Enable the loop back RX used for continuous monitoring, data lane{n}
  [4n+3:4n] SLV_RX_LOOP_BACK_CFG_DL{n} (n=0..4) — Rx loop back configuration for datalane{n} Other: reserved
    0=RX input connected to output pads (clk comp: enabled, comp: disabled); 1=RX input connected before termination (clk comp: enabled, comp: disabled); 2=RX input connected to output pads (clk comp: disabled, comp: enabled); 3=RX input connected before termination (clk comp: disabled, comp: enabled); 4=RX bypassed by cursor signal (clk comp: disabled, comp: disabled)
0x1118 LVDS_PSRLPSR ro — LVDS PHY-slave Rx loopback status register
  [16] SLV_RX_LOOP_BACK_A_DL4 — Rx loop back output for lane0
  [12] SLV_RX_LOOP_BACK_A_DL3 — Rx loop back output for lane1
  [8] SLV_RX_LOOP_BACK_A_DL2 — Rx loop back output for lane2
  [4] SLV_RX_LOOP_BACK_A_DL1 — Rx loop back output for lane3
  [0] SLV_RX_LOOP_BACK_A_DL0 — Rx loop back output for lane4
0x111C LVDS_PSFCR — LVDS PHY-Slave flipedge control register
  [n+16] SLV_FLIP_CLK_EDGE_DL{n} (n=0..4) — Flips the clock edge used by the first analog stage to resample the incoming data stream, data lane{n}
  [n] SLV_FLIP_CLK_EDGE_ANA_DL{n} (n=0..4) — Flips the clock edge used by the pre-driver, data lane{n}
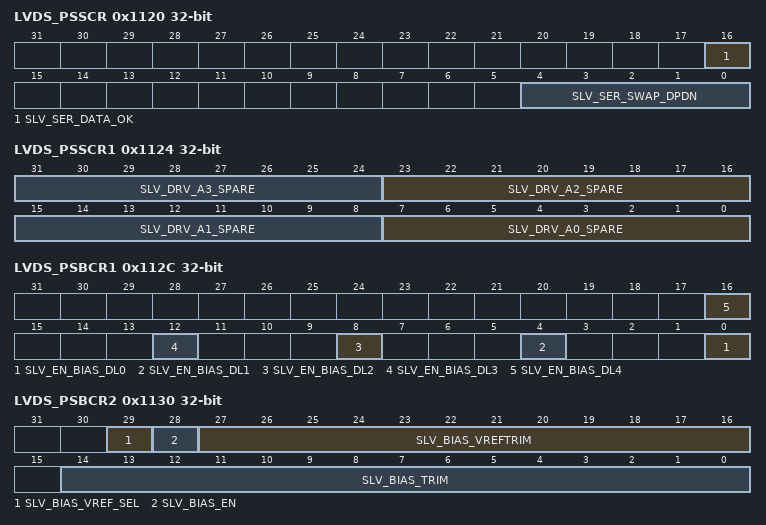
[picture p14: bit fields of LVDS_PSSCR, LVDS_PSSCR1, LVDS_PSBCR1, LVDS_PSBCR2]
0x1120 LVDS_PSSCR — LVDS PHY-Slave serial control register
  [16] SLV_SER_DATA_OK — Indicates transmission of data
    0=No transmission; 1=Transmission
  [4:0] SLV_SER_SWAP_DPDN — Inverts output data 1 bit per lane
0x1124 LVDS_PSSCR1 — LVDS PHY-Slave spare control register 1
  [8n+7:8n] SLV_DRV_A{n}_SPARE (n=0..3) — Spare inputs for data lane{n}
0x1128 LVDS_PSSCR2 — LVDS PHY-Slave spare control register 2
  [7:0] SLV_DRV_A4_SPARE — Spare inputs for data lane4
0x112C LVDS_PSBCR1 — LVDS PHY-Slave bias control register 1
  [all] fields
    0=disable; 1=enable
  [4n] SLV_EN_BIAS_DL{n} (n=0..4) — Enable the local bias at data lane{n}
0x1130 LVDS_PSBCR2 — LVDS PHY-Slave bias control register 2
  [29] SLV_BIAS_VREF_SEL — Selection for current generation internal reference
    0=from the bandgap; 1=from an internal resistive divider
  [28] SLV_BIAS_EN — lvds macro global bias enable
    0=disabled; 1=enabled
  [27:16] SLV_BIAS_VREFTRIM
    1=0.3961V 27.01 uA; 2=0.4252V 23.36 uA; 4=0.4542V 24.96 uA; 8=0.4831V 26.57 uA; 16=0.5120V 28.21 uA; 32=0.5410V 29.90 uA; 64=0.5698V 31.66 uA; 128=0.5985V 33.54 uA; 0x100=0.6272V 35.70 uA; 0x201=0.6557V 38.63 uA; 0x400=0.6838V 43.98 uA; 0x800=0.7107V 56.97 uA
  [14:0] SLV_BIAS_TRIM
    0=27.71uA; 1=27.01 uA; 3=26.32 uA; 7=25.63 uA; 15=24.94 uA; 31=24.24 uA; 63=23.55 uA; 127=22.86 uA; 255=23.55 uA; 0x1FF=24.24 uA; 0x3FF=24.94 uA; 0x7FF=25.63 uA; 0xFFF=26.32 uA; 0x1FFF=27.01 uA; 0x3FFF=27.71 uA; 0x7FFF=28.40 uA
0x1134 LVDS_PSBCR3 — LVDS PHY-Slave bias control register 3
  [4n+2] SLV_VM_USE_VDD_REF_DL{n} (n=0..4) — Sets the voltage mode driver to use a reference derived from the power supply, data lane{n}
  [4n+1] SLV_VM_BOOST_BIAS_DL{n} (n=0..4) — Bias booster for the voltage mode driver LDOS, data lane{n}
    0=bandgap selected; 1=internal resistive divider
  [4n] SLV_VM_EN_DL{n} (n=0..4) — Enable the voltage mode driver for data lane{n}
    0=disable; 1=enable
0x1138 LVDS_PSBCR4 — LVDS PHY-Slave bias control register 4
  [4n+3:4n] SLV_VM_VOUT_VOH_CTRL_DL{n} (n=0..4) — Fine tuning for the voltage mode driver VOH, data lane{n}
0x113C LVDS_PSBCR5 — LVDS PHY-Slave bias control register 5
  [4n+3:4n] SLV_VM_VOUT_VOL_CTRL_DL{n} (n=0..4) — Fine tuning for the voltage mode driver VOL, data lane{n}
0x1140 LVDS_PSICR — LVDS PHY-Slave impedance control register
  [18:16] SLV_IMP_CTRL_DL4 — Impedance control for data lane4
  [14:12] SLV_IMP_CTRL_DL3 — Impedance control for data lane3
  [10:8] SLV_IMP_CTRL_DL2 — Impedance control for data lane0
  [6:4] SLV_IMP_CTRL_DL1 — Impedance control for data lane1
  [2:0] SLV_IMP_CTRL_DL0 — Impedance control for data lane0
0x1144 LVDS_PSMBCCR — LVDS PHY-Slave monitor bandgap current control register
  [24:16] SLV_MON_BG_CURR_UNMASK_TUNE — Bandgap current timing control for the monitor unmask after startup
  [4] SLV_MON_BG_CURR_CLEAR_FAULT — Bandgap current monitor clear fault If set high, lvds_monitor_bg_curr_fault_mst is cleared. It has to be set low again in order to continue monitoring the bandgap current
  [0] SLV_MON_BG_CURR_FORCE_FAULT — Bandgap current monitor force fault If set high, force the lvds_monitor_bg_curr_fault_mst and lvds_monitor_bg_curr_permanent_fault_mst to indicate a fault. This force is only removed once it goes low again
0x1148 LVDS_PSMBCSR ro — LVDS PHY-Slave monitor bandgap current status register
  [4] SLV_MON_BG_CURR_FAULT — Bandgap current monitor fault Indicates that a fault has occurred when high. This signal is latched in the LVDS PHY, so it is kept high until cleared by slv_mon_bg_curr_clear_fault_mst
  [0] SLV_MON_BG_CURR_PERMANENT_FAULT — Bandgap current monitor permanent fault Indicates that a fault is occurring when high. If slv_mon_bg_curr_fault_mst is high and slv_bg_curr_permanent_fault_mst is low, the fault was a glitch that has since faded If slv_mon_bg_curr_fault_mst is high and slv_bg_curr_permanent_fault_mst is high, the fault is still occurring
0x114C LVDS_PSMBLCR — LVDS PHY-Slave monitor bandgap loop control register
  [24:16] SLV_MON_BG_LOOP_UNMASK_TUNE — Bandgap loop timing control for the monitor unmask after startup
  [4] SLV_MON_BG_LOOP_CLEAR_FAULT — Bandgap loop monitor clear fault If set high, lvds_monitor_bg_loop_fault_mst is cleared. It has to be set low again in order to continue monitoring the bandgap loop
  [0] SLV_MON_BG_LOOP_FORCE_FAULT — Bandgap loop monitor force fault If set high, force the lvds_monitor_bg_loop_fault_mst and lvds_monitor_bg_loop_permanent_fault_mst to indicate a fault. This force is only removed once it goes low again
0x1150 LVDS_PSMBLSR ro — LVDS PHY-Slave monitor bandgap loop status register
  [4] SLV_MON_BG_LOOP_FAULT — Bandgap loop monitor fault Indicates that a fault has occurred when high. This signal is latched in the LVDS PHY, so it is kept high until cleared by slv_mon_bg_loop_clear_fault_mst
  [0] SLV_MON_BG_LOOP_PERMANENT_FAULT — Bandgap loop monitor permanent fault Indicates that a fault is occurring when high. If slv_mon_bg_loop_fault_mst is high and slv_bg_loop_permanent_fault_mst is low, the fault was a glitch that has since faded If slv_mon_bg_loop_fault_mst is high and slv_bg_loop_permanent_fault_mst is high, the fault is still occurring
0x1154 LVDS_PSMBOVCR — LVDS PHY-Slave monitor bandgap output voltage control register
  [24:16] SLV_MON_BG_VOLT_UNMASK_TUNE — Bandgap output voltage timing control for the monitor unmask after startup
  [4] SLV_MON_BG_VOLT_CLEAR_FAULT — Bandgap output voltage monitor clear fault If set high, lvds_monitor_bg_volt_fault_mst is cleared. It has to be set low again in order to continue monitoring the bandgap output voltage
  [0] SLV_MON_BG_VOLT_FORCE_FAULT — Bandgap output voltage monitor force fault If set high, force the lvds_monitor_bg_volt_fault_mst and lvds_monitor_bg_volt_permanent_fault_mst to indicate a fault. This force is only removed once it goes low again
0x1158 LVDS_PSMBOVSR ro — LVDS PHY-Slave monitor bandgap output voltage status register
  [4] SLV_MON_BG_VOLT_FAULT — Bandgap output voltage monitor fault Indicates that a fault has occurred when high. This signal is latched in the LVDS PHY, so it is kept high until cleared by slv_mon_bg_volt_clear_fault_mst
  [0] SLV_MON_BG_VOLT_PERMANENT_FAULT — Bandgap output voltage monitor permanent fault Indicates that a fault is occurring when high. If slv_mon_bg_volt_fault_mst is high and slv_bg_volt_permanent_fault_mst is low, the fault was a glitch that has since faded If slv_mon_bg_volt_fault_mst is high and slv_bg_volt_permanent_fault_mst is high, the fault is still occurring
0x1174 LVDS_PSMSCCR — LVDS PHY-Slave monitor serializer clock control register
  [4] SLV_SER_CLK_CLEAR_FAULT — Serializer clock checking fault clearing
  [0] SLV_SER_CLK_ERROR_INJ — Serializer clock checking error injection
0x1178 LVDS_PSMSCSR ro — LVDS PHY-Slave monitor serializer clock status register
  [0] SLV_SER_CLK_FAULT — Serializer clock checking fault
0x117C LVDS_PSMSCR — LVDS PHY-Slave monitor serializer control register
  [20:16] SLV_SER_LPBCK — Serializer fault loopback
  [12:8] SLV_SER_FAULT_CLEAR — Serializer fault clearing
  [4:0] SLV_SER_ERROR_INJ — Serializer error injection
0x1180 LVDS_PSMSSR ro — LVDS PHY-Slave monitor serializer status register
  [4:0] SLV_SER_FAULT — Serializer fault
0x1184 LVDS_PSDCR — LVDS PHY-Slave debug control register
  [12] SLV_POWER_OK — When set to 1, this bit masks some functions in the LVDS-PHY. This bit can be used as a work around to functional problems with some of the monitor blocks
  [0] SLV_FORCE_ANALOG_OK — When set to 1, this bit masks some functions in the LVDS-PHY. This bit can be used as a work around to functional problems with some of the monitor blocks
0x1188 LVDS_PSSSR1 ro — LVDS PHY-Slave spare status register 1
  [8n+7:8n] SLV_DRV_A{n}_SPARE_RD (n=0..3) — Spare outputs for data lane{n}
0x118C LVDS_PSSSR2 ro — LVDS PHY-Slave spare status register 2
  [7:0] SLV_DRV_A4_SPARE_RD — Spare outputs for data lane4
0x11A0 LVDS_PSCFGCR — LVDS PHY-Slave configuration control register
  [4:0] SLV_EN_DIG_DL — Enables Digital DataLanes DL4...DL0
0x11C0 LVDS_PSPLLCR1 — LVDS PHY-Slave PLL_MODE 1 control register
  [12] SLV_PLL_BYPASS_START_DECT ro — Bypass start DECT.
  [8] SLV_PLL_DIVIDERS_ENABLE — 0x0: Dividers disabled
    1=Dividers enabled
  [4] SLV_PLL_BYPASS — 0x0: from VCO output
    1=from external (lvds_pll_clk_bypass_2g2)
  [2] SLV_PLL_TWG_ENABLE — Triangular wave pattern used to modulate MDIV
    0=Triangular wave generator powered down; 1=Triangular wave generator enable (not recommended if integer N PLL mode is selected)
  [1] SLV_PLL_SD_ENABLE — sigma-delta enable
    0=disable (Integer N PLL mode); 1=enable (fractional N PLL mode if SLV_PLL_twg_enable=0 , spread spectrum clocking if SLV_PLL_twg_enable=1)
  [0] SLV_PLL_ENABLE — 0x0: LVDS-PHY PLL Disable
    1=LVDS-PHY PLL Enable
0x11C4 LVDS_WCLKCR — LVDS wrapper clock control register
  [8] SRCSEL — Source Selection for the Pixel Clock, between master and slave PHY: Note: Both the double-pixel clock and the lock are selected from the relevant PHY and its PLL.
    0=from the Master PHY; 1=from the Slave PHY
  [0] SLV_CLKPIX_SEL — Pixel clock selection:
    0=LVDS PLL reference clock (from RCC); 1=LVDS PLL output dual-pixel clock
0x11C4 LVDS_PSPLLCR2 (alternate view of LVDS_WCLKCR) — LVDS PHY-Slave PLL_MODE 2 control register
  [25:16] SLV_PLL_INPUT_DIV — PLL Input Clock Divider (NDIV, divides input reference clock)
    1=B_d1 (minimal value)
  [9:0] SLV_PLL_BIT_DIV — PLL Output Clock Divider (BDIV, divides output VCO)
    2=B_d2 (minimal value)
0x11C8 LVDS_PSPLLSR ro — LVDS PHY-Slave PLL status register
  [0] SLV_PLL_LOCK — PLL lock During a certain number of cycles of reference clock, pll_lock is asserted high and then goes low waiting for the LVDS-PHY PLL t0 lock
0x11CC LVDS_PSPLLSDCR1 — LVDS PHY-Slave PLL_SD_1 control register
  [9:0] SLV_PLL_SD_INT_RATIO — Integer Setting of PLL Feedback Clock Divider (MDIV, divides VCO clock for feedback). MDIV divider is used for both integer N and Fractional N PLL modes: - Integer N: MDIV = SLV_PLL_sd_int_ratio[9:0] (for integer setting) SLV_PLL_sd_bypass_vco_mux is not used. - Fractional N: MDIV = SLV_PLL_sd_int_ratio[9:0] (for integer setting), SLV_PLL_sd_input_code_bypass[22:0] (for fractional setting). MDIV = SLV_PLL_sd_int_ratio[9:0] + (SLV_PLL_sd_input_code_bypass[22:0 - 4194304)/131072
0x11D0 LVDS_PSPLLSDCR2 reset 0xF — LVDS PHY-Slave PLL_SD_2 control register
  [28] SLV_PLL_SD_CLK_EDGE_CNTRL — Sigma--delta edge control.
  [26] SLV_PLL_SD_BYPASS_FB_CLK ro — Bypass start SD feedback clock.
  [25:24] SLV_PLL_SD_BYPASS_VCO_MUX — Bypass control for the PLL sigma delta VCO mux
  [22:0] SLV_PLL_SD_INPUT_CODE_BYPASS — Fractional Setting of PLL feedback clock Divider (MDIV, divides VCO clock for feedback)
0x11D4 LVDS_PSPLLTWGCR1 — LVDS PHY-Slave PLL_TWG_1 control register
  [20] SLV_PLL_TWG_DOWN_SPREAD — TWG pattern spreading
    0=center spread; 1=down spread
  [19:0] SLV_PLL_TWG_STEP — MDIV divdier used in integer N and Fractional N PLL modes integer N: SLV_PLL_sd_bypass_vco_mux is not relevant. MDIV = SLV_PLL_sd_int_ratio[9:0] fractional N: MDIV controlled by SLV_PLL_sd_int_ratio[9:0] and SLV_PLL_sd_input_code_bypass[22:0] MDIV = SLV_PLL_sd_int_ratio[9:0] + (SLV_PLL_sd_input_code_bypass[22:0 - 4194304)/131072
0x11D8 LVDS_PSPLLTWGCR2 — LVDS PHY-Slave PLL_TWG_2 control register
  [22:0] SLV_PLL_TWG_THRESHOLD — TWG_THRESHOLD setting
0x11DC LVDS_PSPLLLDOCR — LVDS PHY-Slave PLL_LDO control register
  [2:0] SLV_PLL_LDO_FRREGVTRIM — PLL LDO output voltage fine tuning:
    values as LVDS_PMPLLLDOCR.MST_PLL_LDO_FRREGVTRIM
0x11E0 LVDS_PSPLLCPCR — LVDS PHY-Slave PLL_CP control register
  [3:0] SLV_PLL_CPCTRL — PLL charge pump control, default=1.
0x11E4 LVDS_PSPLLCFGCR — LVDS PHY-Slave PLL_CFG control register
  [7:0] SLV_PLL_CFG — PLL configuration
0x11E8 LVDS_PSPLLTESTCR reset 0x10000 — LVDS PHY-Slave PLL_TEST control register
  [25:16] SLV_PLL_TEST_DIV_SETTINGS — lvds_pll_test_clk dividers value
  [8] SLV_PLL_TEST_DIV_EN — lvds_pll_test_clk dividers enable
    0=disable; 1=enable
  [0] SLV_PLL_TEST_CLK_EN — lvds_pll_test_clk enable
    0=disable; 1=enable
0x1200 LVDS_PMATCR1 — LVDS PHY-Master analog test control register 1
  [all] fields
    128=Current mode driver test current; 64=Current mode driver test current; 32=internal 1.2V reference; 16=internal 0.775V reference; 8=output of the LDO which sets VOL; 4=output of the LDO which sets VOH; 2=Feedback loop of the LDO which sets VOL; 1=Output of the RX loopback; 0=tristate
  [31:24] PMATDL3 — PHY-Master analog test data lane 3 Analog test mux control for mst_lvds_ana_test output, for data lane 3.
  [23:16] PMATDL2 — PHY-Master analog test data lane 2 Analog test mux control for mst_lvds_ana_test output, for data lane 2:
  [15:8] PMATDL1 — PHY-Master analog test data lane 1 Analog test mux control for mst_lvds_ana_test output, for data lane 1.
  [7:0] PMATDL0 — PHY-Master analog test data lane 0 Analog test mux control for mst_lvds_ana_test output, for data lane 0.
0x1204 LVDS_PMATCR2 — LVDS PHY-Master analog test control register 2
  [22:16] PMATPC — Phy-Master analog test PLL control PLL master analog test miux control for mst_lvds_ana_test output.
    64=vcp_sup (internal 1.4 V VCO LDO output); 32=vctrl (VCO control voltage number 1, expected value is 1.4 V-0.7 V); 16=vcap (VCO control voltage number 2, expected value is 1.4 V-0.7 V); 8=icp_test (Charge pump current replica, expected value is 5uA); 4=pll_lock (PLL lock indication, sets to DVDD_CORE when the PLL is powered up, 0Votherwise); 2=ref_ok (PLL reference presence indication, sets to DVDD_CORE when the PLL is powered up and the reference, 0V otherwise); 1=AVSS_IO; 0=tristate
  [15:8] PMATB — Phy-Master analog test bias Bias analog test mux control for mst_lvds_ana_test output.
    128=Local ground (0 V); 64=Local ground (0 V); 32=internal reference for the current generator block, 0.5 V; 16=Local ground (0 V); 8=Bandgap diode (0.7 V); 4=12.5 uA reference current, measured referred to ground; 2=internal reference for the current generator block, 0.5 V; 1=internal filtered AVDD_CORE; 0=tristate
  [7:0] PMATDL4 — PHY-Master analog test data lane 4 Analog test mux control for mst_lvds_ana_test output, for data lane 4.
    128=Current mode driver test current; 64=Current mode driver test current; 32=internal 1.2 V reference; 16=internal 0.775 V reference; 8=output of the LDO which sets VOL; 4=output of the LDO which sets VOH; 2=Feedback loop of the LDO which sets VOL; 1=Output of the RX loopback; 0=tristate
0x1208 LVDS_PMDTCR1 — LVDS PHY-Master digital test control register 1
  [all] fields
    128=Driver bias enable; 64=Enables the voltage mode driver; 32=Enables the current mode driver; 8=internal VOH LDP output; 4=internal VOL LDO output; 2=internal o_int_rx_loop_back; 1=internal i_en_loop_back; 0=tristate
  [31:24] PMDTDL3 — PHY-Master digital test data lane 3 Data lane 3 digital test mux control for mst_lvds_dig_test_dl3.
  [23:16] PMDTDL2 — PHY-Master digital test data lane 2 Data lane 2 digital test mux control for mst_lvds_dig_test_dl2.
  [15:8] PMDTDL1 — PHY-Master digital test data lane 1 Data lane 3 digital test mux control for mst_lvds_dig_test_dl1.
  [7:0] PMDTDL0 — PHY-Master digital test data lane 0 Data lane 0 digital test mux control for mst_lvds_dig_test_dl0.
0x120C LVDS_PMDTCR2 — LVDS PHY-Master digital test control register 2
  [14:8] PMDTMC — Phy-Master digital test mux control PLL master digital test mux control for o_lvds_pll_dig_test.
    64=Output of the input divider; 32=Input reference; 16=Lock detector monitor; 8=Reference OK monitor; 4=Feedback divider output clock; 2=PLL RFD DN signal; 1=PLL PFD UP signal
  [7:0] PMDTDL4 — PHY-Master digital test data lane 4 Data lane 4 digital test mux control for mst_lvds_dig_test_dl4.
    values as the fields of LVDS_PMDTCR1
0x1210 LVDS_PMDTSR ro — LVDS PHY-Master digital test status register
  [5] PMDTPS — Phy-Master digital test PLL status
  [4] PMDTDLS4 — Phy-Master digital test data lane status 4
  [3] PMDTDLS3 — Phy-Masterdigital test data lane status 3
  [2] PMDTDLS2 — Phy-Master digital test data lane status 2
  [1] PMDTDLS1 — Phy-Master digital test data lane status 1
  [0] PMDTDLS0 — Phy-Master digital test data lane status 0
0x1220 LVDS_PSATCR1 — LVDS PHY-Slave analog test control register 1
  [all] fields
    values as LVDS_PMATCR2.PMATDL4
  [31:24] PSATDL3 — PHY Slave analog test data lane 3 Analog test mux control for mst_lvds_ana_test output, for data lane 3.
  [23:16] PSATDL2 — PHY-Slave analog test data lane 2 Analog test mux control for mst_lvds_ana_test output, for data lane 2.
  [15:8] PSATDL1 — PHY-Slave analog test data lane 1 Analog test mux control for mst_lvds_ana_test output, for data lane 1.
  [7:0] PSATDL0 — PHY-Slave analog test data lane 4 Analog test mux control for mst_lvds_ana_test output, for data lane 4.
0x1224 LVDS_PSATCR2 — LVDS PHY-Slave analog test control register 2
  [22:16] PSATPC — Phy-Slave analog test PLL control PLL slave analog test miux control for mst_lvds_ana_test output
    64=vcp_sup (internal 1.4 V VCO LDO output); 32=vctrl (VCO control voltage number 1, expected value is 1.4 V-0.7 V); 16=vcap (VCO control voltage number 2, expected value is 1.4 V-0.7 V); 8=icp_test (Charge pump current replica, expected value is 5 uA); 4=pll_lock (PLL lock indication, sets to DVDD_CORE when PLL is powered up, 0Votherwise); 2=ref_ok (PLL reference presence indication, sets to DVDD_CORE when the PLL is powered up and the reference, 0V otherwise); 1=AVSS_IO; 0=tristate
  [15:8] PSATB — Phy-Slave analog test bias Bias analog test mux control for mst_lvds_ana_test output
    128=Local ground (0 V); 64=Local ground (0 V); 32=internal reference for the current generator block, 0.5 V; 16=Local ground, 0V; 8=Bandgap diode (0.7 V); 4=12.5 uA reference current, measured referred to ground; 2=internal reference for the current generator block, 0.5 V; 1=internal filtered AVDD_CORE; 0=tristate
  [7:0] PSATDL4 — PHY-Slave analog test data lane 4 Analog test mux control for mst_lvds_ana_test output, for data lane 4.
    values as LVDS_PMATCR2.PMATDL4
0x1228 LVDS_PSDTCR1 — LVDS PHY-Slave digital test control register 1
  [all] fields
    values as the fields of LVDS_PMDTCR1
  [31:24] PSDTDL3 — PHY-Slave digital test data lane 3 Data lane 3 digital test mux control for mst_lvds_dig_test_dl3.
  [23:16] PSDTDL2 — PHY-Slave digital test data lane 2 Data lane 2digital test mux control for mst_lvds_dig_test_dl2:
  [15:8] PSDTDL1 — PHY-Slave digital test data lane 1 Data lane 3 digital test mux control for mst_lvds_dig_test_dl1.
  [7:0] PSDTDL0 — PHY-Slave digital test data lane 0 Data lane 0 digital test mux control for mst_lvds_dig_test_dl0.
0x122C LVDS_PSDTCR2 — LVDS PHY-Slave digital test control register 2
  [14:8] PSDTMC — PHY-Slave digital test PLL master digital test mux control for o_lvds_pll_dig_test. Other: reserved
    values as LVDS_PMDTCR2.PMDTMC
  [7:0] PSDTDL4 — PHY-Slave digital test data lane 4 Data lane 4 digital test mux control for slv_lvds_dig_test_dl4:
    values as the fields of LVDS_PMDTCR1
0x1230 LVDS_PSDTSR — LVDS PHY-Slave digital test status register
  [5] PSDTPS — Phy-Slave digital test PLL status
  [n] PSDTDLS{n} (n=0..4) — Phy-Slave digital test data lane status {n}
0x1FF0 LVDS_HWCFGR ro reset 0x251 — LVDS hardware configuration register
  [11:8] LINKS — amount of LVDS PHY links
    0=information not defined; 1=One LVDS Llnk; 2=Two LVDS links (used as either dual link or two independent links)
  [7:4] LANES — amount of LVDS PHY Lanes (including the LVDS PHY clock lane) in one link
    0=information not defined; 4=3 DataLanes + 1 ClockLane, which suits for RGB666; 5=4 DataLanes + 1 ClockLane, which suits for RGB888 (or backward RGB666)
  [3:0] TECHNO — PHY technology (and version)
    0=information not defined; 1=16FF (Cadence OpenLDI PHY spec v1.2)
0x1FF4 LVDS_VERR ro reset 0x20 — LVDS version register
  [7:4] MAJREV — LVDS PHY host major revision
  [3:0] MINREV — LVDS PHY host minor revision
0x1FF8 LVDS_IPIDR ro reset 0x1600A1 — LVDS identification register
  [31:0] IDR — LVDS PHY host identification (0x0016_00A1)
0x1FFC LVDS_SIDR ro reset 0xA3C5DD08 — LVDS size register
  [31:0] SID — LVDS PHY host address space: 8 Kbytes (4 K for host, 4 K for PHY/Wrapper)
